AUTOSAR XML (schema 4-2-2)
package /STELLANTIS/EPT/ASWCs
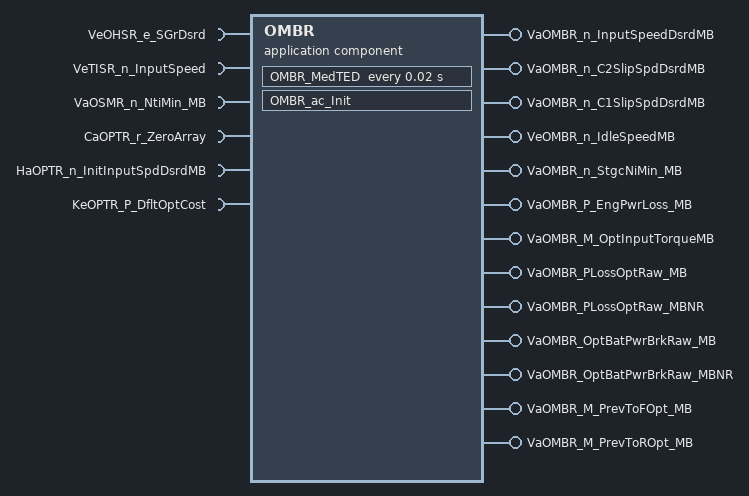
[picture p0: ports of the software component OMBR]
  application sw component type OMBR
    require port VeOHSR_e_SGrDsrd: nonqueued-receiver-com-spec{data-element=Value, init-value=CeOHSR_e_SG_Reverse}, required-interface=VeOHSR_e_SGrDsrd
    require port VeTISR_n_InputSpeed: nonqueued-receiver-com-spec{data-element=Value, init-value=0}, required-interface=VeTISR_n_InputSpeed
    require port VaOSMR_n_NtiMin_MB: nonqueued-receiver-com-spec{data-element=Value, init-value=9 x 0}, required-interface=VaOSMR_n_NtiMin_MB
    13 x provide port:
      VaOMBR_n_InputSpeedDsrdMB: nonqueued-sender-com-spec{data-element=Value, init-value=9 x 0}, provided-interface=VaOMBR_n_InputSpeedDsrdMB
      VaOMBR_n_C2SlipSpdDsrdMB: nonqueued-sender-com-spec{data-element=Value, init-value=9 x 0}, provided-interface=VaOMBR_n_C2SlipSpdDsrdMB
      VaOMBR_n_C1SlipSpdDsrdMB: nonqueued-sender-com-spec{data-element=Value, init-value=9 x 0}, provided-interface=VaOMBR_n_C1SlipSpdDsrdMB
      VeOMBR_n_IdleSpeedMB: nonqueued-sender-com-spec{data-element=Value, init-value=0}, provided-interface=VeOMBR_n_IdleSpeedMB
      VaOMBR_n_StgcNiMin_MB: nonqueued-sender-com-spec{data-element=Value, init-value=9 x 0}, provided-interface=VaOMBR_n_StgcNiMin_MB
      VaOMBR_P_EngPwrLoss_MB: nonqueued-sender-com-spec{data-element=Value, init-value=9 x 0}, provided-interface=VaOMBR_P_EngPwrLoss_MB
      VaOMBR_M_OptInputTorqueMB: nonqueued-sender-com-spec{data-element=Value, init-value=9 x 0}, provided-interface=VaOMBR_M_OptInputTorqueMB
      VaOMBR_PLossOptRaw_MB: nonqueued-sender-com-spec{data-element=Value, init-value=9 x 0}, provided-interface=VaOMBR_PLossOptRaw_MB
      VaOMBR_PLossOptRaw_MBNR: nonqueued-sender-com-spec{data-element=Value, init-value=9 x 0}, provided-interface=VaOMBR_PLossOptRaw_MBNR
      VaOMBR_OptBatPwrBrkRaw_MB: nonqueued-sender-com-spec{data-element=Value, init-value=9 x 0}, provided-interface=VaOMBR_OptBatPwrBrkRaw_MB
      VaOMBR_OptBatPwrBrkRaw_MBNR: nonqueued-sender-com-spec{data-element=Value, init-value=9 x 0}, provided-interface=VaOMBR_OptBatPwrBrkRaw_MBNR
      VaOMBR_M_PrevToFOpt_MB: nonqueued-sender-com-spec{data-element=Value, init-value=9 x 0}, provided-interface=VaOMBR_M_PrevToFOpt_MB
      VaOMBR_M_PrevToROpt_MB: nonqueued-sender-com-spec{data-element=Value, init-value=9 x 0}, provided-interface=VaOMBR_M_PrevToROpt_MB
    require port CaOPTR_r_ZeroArray: parameter-require-com-spec{init-value=CaOPTR_r_ZeroArray_CaOPTR_r_ZeroArray:[CaOPTR_r_ZeroArray_CaOPTR_r_ZeroArray_rt_Array_Float_9_1:0, CaOPTR_r_ZeroArray_CaOPTR_r_ZeroArray_rt_Array_Float_9_2:0, CaOPTR_r_ZeroArray_CaOPTR_r_ZeroArray_rt_Array_Float_9_3:0, CaOPTR_r_ZeroArray_CaOPTR_r_ZeroArray_rt_Array_Float_9_4:0, CaOPTR_r_ZeroArray_CaOPTR_r_ZeroArray_rt_Array_Float_9_5:0, CaOPTR_r_ZeroArray_CaOPTR_r_ZeroArray_rt_Array_Float_9_6:0, CaOPTR_r_ZeroArray_CaOPTR_r_ZeroArray_rt_Array_Float_9_7:0, CaOPTR_r_ZeroArray_CaOPTR_r_ZeroArray_rt_Array_Float_9_8:0, CaOPTR_r_ZeroArray_CaOPTR_r_ZeroArray_rt_Array_Float_9_9:0], parameter=CaOPTR_r_ZeroArray}, required-interface=CaOPTR_r_ZeroArray
    require port HaOPTR_n_InitInputSpdDsrdMB: parameter-require-com-spec{init-value=9 x 500, parameter=HaOPTR_n_InitInputSpdDsrdMB}, required-interface=HaOPTR_n_InitInputSpdDsrdMB
    require port KeOPTR_P_DfltOptCost: parameter-require-com-spec{init-value=KeOPTR_P_DfltOptCost_KeOPTR_P_DfltOptCost:1000000, parameter=KeOPTR_P_DfltOptCost}, required-interface=KeOPTR_P_DfltOptCost
    behavior IB_OMBR: data-type-mapping=msADTtoIDTMapping, handle-termination-and-restart=NO-SUPPORT, included-data-type-set=data-type=TeTSXR_e_PrfrdComb
      timing event Event_MedTED: start-on-event=OMBR_MedTED, period=0.02
      init event Event_OMBR_ac_Init: start-on-event=OMBR_ac_Init
      runnable OMBR_ac_Init
        data-send-points:
          13 x access:
            OUT_VaOMBR_n_StgcNiMin_MB_Value: accessed-variable=VaOMBR_n_StgcNiMin_MB.Value
            OUT_VaOMBR_n_C1SlipSpdDsrdMB_Value: accessed-variable=VaOMBR_n_C1SlipSpdDsrdMB.Value
            OUT_VaOMBR_n_C2SlipSpdDsrdMB_Value: accessed-variable=VaOMBR_n_C2SlipSpdDsrdMB.Value
            OUT_VaOMBR_n_InputSpeedDsrdMB_Value: accessed-variable=VaOMBR_n_InputSpeedDsrdMB.Value
            OUT_VeOMBR_n_IdleSpeedMB_Value: accessed-variable=VeOMBR_n_IdleSpeedMB.Value
            OUT_VaOMBR_PLossOptRaw_MB_Value: accessed-variable=VaOMBR_PLossOptRaw_MB.Value
            OUT_VaOMBR_P_EngPwrLoss_MB_Value: accessed-variable=VaOMBR_P_EngPwrLoss_MB.Value
            OUT_VaOMBR_OptBatPwrBrkRaw_MBNR_Value: accessed-variable=VaOMBR_OptBatPwrBrkRaw_MBNR.Value
            OUT_VaOMBR_M_OptInputTorqueMB_Value: accessed-variable=VaOMBR_M_OptInputTorqueMB.Value
            OUT_VaOMBR_OptBatPwrBrkRaw_MB_Value: accessed-variable=VaOMBR_OptBatPwrBrkRaw_MB.Value
            OUT_VaOMBR_PLossOptRaw_MBNR_Value: accessed-variable=VaOMBR_PLossOptRaw_MBNR.Value
            OUT_VaOMBR_M_PrevToFOpt_MB_Value: accessed-variable=VaOMBR_M_PrevToFOpt_MB.Value
            OUT_VaOMBR_M_PrevToROpt_MB_Value: accessed-variable=VaOMBR_M_PrevToROpt_MB.Value
        parameter access CALPRM_CaOPTR_r_ZeroArray_CaOPTR_r_ZeroArray: accessed-parameter=CaOPTR_r_ZeroArray.CaOPTR_r_ZeroArray
        parameter access CALPRM_HaOPTR_n_InitInputSpdDsrdMB_HaOPTR_n_InitInputSpdDsrdMB: accessed-parameter=HaOPTR_n_InitInputSpdDsrdMB.HaOPTR_n_InitInputSpdDsrdMB
        parameter access CALPRM_KeOPTR_P_DfltOptCost_KeOPTR_P_DfltOptCost: accessed-parameter=KeOPTR_P_DfltOptCost.KeOPTR_P_DfltOptCost
      runnable OMBR_MedTED
        data-receive-point-by-arguments:
          access IN_VaOSMR_n_NtiMin_MB_Value: accessed-variable=VaOSMR_n_NtiMin_MB.Value
          access IN_VeTISR_n_InputSpeed_Value: accessed-variable=VeTISR_n_InputSpeed.Value
        data-send-points:
          13 x access:
            OUT_VaOMBR_n_InputSpeedDsrdMB_Value: accessed-variable=VaOMBR_n_InputSpeedDsrdMB.Value
            OUT_VaOMBR_n_C1SlipSpdDsrdMB_Value: accessed-variable=VaOMBR_n_C1SlipSpdDsrdMB.Value
            OUT_VaOMBR_n_C2SlipSpdDsrdMB_Value: accessed-variable=VaOMBR_n_C2SlipSpdDsrdMB.Value
            OUT_VeOMBR_n_IdleSpeedMB_Value: accessed-variable=VeOMBR_n_IdleSpeedMB.Value
            OUT_VaOMBR_n_StgcNiMin_MB_Value: accessed-variable=VaOMBR_n_StgcNiMin_MB.Value
            OUT_VaOMBR_P_EngPwrLoss_MB_Value: accessed-variable=VaOMBR_P_EngPwrLoss_MB.Value
            OUT_VaOMBR_M_OptInputTorqueMB_Value: accessed-variable=VaOMBR_M_OptInputTorqueMB.Value
            OUT_VaOMBR_PLossOptRaw_MB_Value: accessed-variable=VaOMBR_PLossOptRaw_MB.Value
            OUT_VaOMBR_PLossOptRaw_MBNR_Value: accessed-variable=VaOMBR_PLossOptRaw_MBNR.Value
            OUT_VaOMBR_OptBatPwrBrkRaw_MB_Value: accessed-variable=VaOMBR_OptBatPwrBrkRaw_MB.Value
            OUT_VaOMBR_OptBatPwrBrkRaw_MBNR_Value: accessed-variable=VaOMBR_OptBatPwrBrkRaw_MBNR.Value
            OUT_VaOMBR_M_PrevToFOpt_MB_Value: accessed-variable=VaOMBR_M_PrevToFOpt_MB.Value
            OUT_VaOMBR_M_PrevToROpt_MB_Value: accessed-variable=VaOMBR_M_PrevToROpt_MB.Value
        parameter access CALPRM_CaOPTR_r_ZeroArray_CaOPTR_r_ZeroArray: accessed-parameter=CaOPTR_r_ZeroArray.CaOPTR_r_ZeroArray
        parameter access CALPRM_HaOPTR_n_InitInputSpdDsrdMB_HaOPTR_n_InitInputSpdDsrdMB: accessed-parameter=HaOPTR_n_InitInputSpdDsrdMB.HaOPTR_n_InitInputSpdDsrdMB
        parameter access CALPRM_KeOPTR_P_DfltOptCost_KeOPTR_P_DfltOptCost: accessed-parameter=KeOPTR_P_DfltOptCost.KeOPTR_P_DfltOptCost
      21 x variation point proxy, all with category=CONDITION:
        Variant_HSCL_3Mot_Enbl: condition-access=0
        Variant_OMBR_EnblMB: condition-access=0
        Variant_OMBR_EnblMBIdl: condition-access=0
        Variant_OMBR_EnblMtrBChrgLim: condition-access=0
        Variant_OPTR_EVRngStwTCC: condition-access=0
        Variant_OPTR_Enbl3MtrSys: condition-access=0
        Variant_OPTR_EnblPwrPnlCnstr: condition-access=0
        Variant_OPTR_EnblTCCCalc: condition-access=0
        Variant_OPTR_EnblWEDRsrv: condition-access=1
        Variant_OPTR_HiResSrchNiPiLims: condition-access=0
        Variant_OPTR_MBNRActive: condition-access=0
        Variant_OPTR_OptBatPwrBrkEnbl: condition-access=1
        Variant_OPTR_TCCUseNiMaxTbl: condition-access=1
        Variant_OPTR_ZrPdlToMinAtTeMin: condition-access=0
        Variant_SCOR_MtrxSelP1P2p5: condition-access=0
        Variant_TSXR_MtrALimToFSel: condition-access=1
        Variant_TSXR_MtrALimToRSel: condition-access=0
        Variant_TSXR_MtrBLimToFSel: condition-access=0
        Variant_TSXR_MtrBLimToRSel: condition-access=1
        Variant_TSXR_MtrCLimToFSel: condition-access=0
        Variant_TSXR_MtrCLimToRSel: condition-access=0
